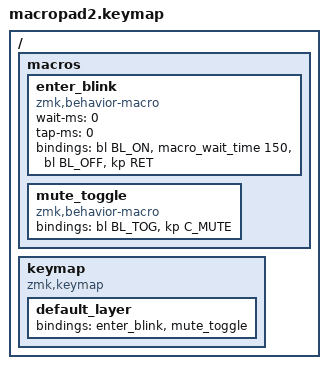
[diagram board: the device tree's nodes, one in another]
/*
 * Copyright (c) 2020 The ZMK Contributors
 *
 * SPDX-License-Identifier: MIT
 */

#include <behaviors.dtsi>
#include <dt-bindings/zmk/keys.h>
#include <dt-bindings/zmk/backlight.h>

/ {
    macros {
        /* Enter: LED berkedip sebentar lalu mati */
        enter_blink: enter_blink {
            compatible = "zmk,behavior-macro";
            #binding-cells = <0>;
            wait-ms = <0>;
            tap-ms = <0>;
            bindings
                = <&bl BL_ON>
                , <&macro_wait_time 150>
                , <&bl BL_OFF>
                , <&kp RET>;
        };

        /* Mute: LED toggle mengikuti status mute */
        mute_toggle: mute_toggle {
            compatible = "zmk,behavior-macro";
            #binding-cells = <0>;
            bindings
                = <&bl BL_TOG>
                , <&kp C_MUTE>;
        };
    };

    keymap {
        compatible = "zmk,keymap";

        default_layer {
            bindings = <
                &enter_blink   &mute_toggle
            >;
        };
    };
};
